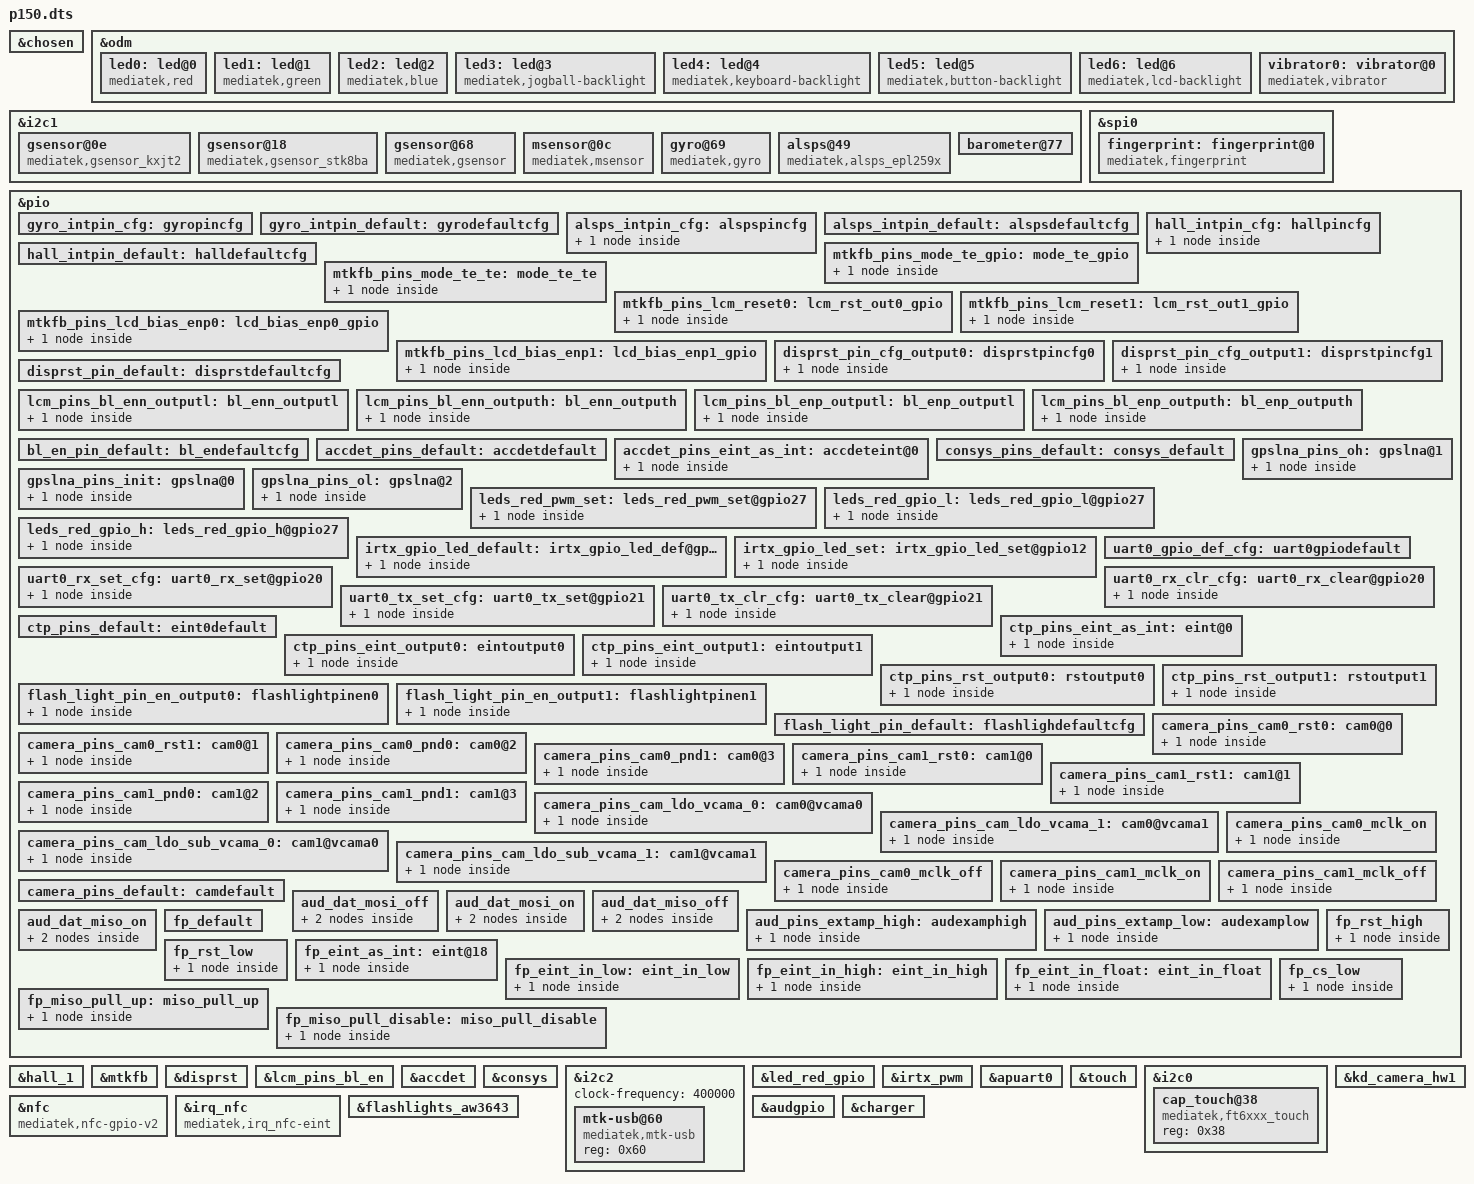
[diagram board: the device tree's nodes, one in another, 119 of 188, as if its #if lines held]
#include <generated/autoconf.h>
/dts-v1/;

#ifdef CONFIG_MTK_DTBO_FEATURE
/plugin/;
#include <dt-bindings/mmc/mt6739-msdc.h>
#include <dt-bindings/pinctrl/mt6739-pinfunc.h>
#else
#include "mt6739.dts"
#endif

#include <dt-bindings/clock/mt6739-clk.h>
#include <dt-bindings/interrupt-controller/arm-gic.h>
#include <dt-bindings/interrupt-controller/irq.h>

/* chosen */
&chosen {
	bootargs = "console=tty0 console=ttyMT0,921600n1 root=/dev/ram initrd=0x44000000,\
0x1000000 loglevel=8 androidboot.selinux=permissive androidboot.hardware=mt6739 initcall_debug=1";
	/* fpga may has no lk, we need to specify display info here */
	/* fb buffer is reserved using this dts by memory node above */

	atag,videolfb-fb_base_l = <0x5e605000>;
	atag,videolfb-fb_base_h = <0>;
	atag,videolfb-islcmfound = <1>;
	atag,videolfb-islcm_inited = <0>;
	atag,videolfb-fps= <6000>;
	atag,videolfb-vramSize= <0x017bb000>;
	atag,videolfb-lcmname= "nt35521_hd_dsi_vdo_truly_nt50358_drv";
};

&odm {
	led0:led@0 {
		compatible = "mediatek,red";
		led_mode = <1>;
		data = <2>;
		pwm_config = <0 0 0 0 0>;
	};
	led1:led@1 {
		compatible = "mediatek,green";
		led_mode = <3>;
		data = <2>;
		pwm_config = <0 0 0 0 0>;
	};
	led2:led@2 {
		compatible = "mediatek,blue";
		led_mode = <0>;
		data = <1>;
		pwm_config = <0 0 0 0 0>;
	};
	led3:led@3 {
		compatible = "mediatek,jogball-backlight";
		led_mode = <0>;
		data = <1>;
		pwm_config = <0 0 0 0 0>;
	};
	led4:led@4 {
		compatible = "mediatek,keyboard-backlight";
		led_mode = <0>;
		data = <1>;
		pwm_config = <0 0 0 0 0>;
	};
	led5:led@5 {
		compatible = "mediatek,button-backlight";
		led_mode = <0>;
		data = <1>;
		pwm_config = <0 0 0 0 0>;
	};
	led6:led@6 {
		compatible = "mediatek,lcd-backlight";
		led_mode = <5>;
		data = <1>;
		pwm_config = <0 0 0 0 0>;
	};
	vibrator0:vibrator@0 {
		compatible = "mediatek,vibrator";
		vib_timer = <25>;
		vib_limit = <9>;
		vib_vol= <9>;
	};
};


&i2c1 {
/*  start sensor */
	/*  KXTJ3, compatible with kxjt2 code*/
	gsensor@0e {
		compatible = "mediatek,gsensor_kxjt2";
		reg = <0x0e>;
		i2c_num	= <1>;
		i2c_addr = <0x0e 0 0 0>;
		direction = <1>;
		power_id = <0xffff>;
		power_vol = <0>;
		firlen = <16>;
		is_batch_supported = <0>;
	};

	gsensor@18 {
		compatible = "mediatek,gsensor_stk8ba";
		reg = <0x18>;
		i2c_num	= <1>;
		i2c_addr = <0x18 0 0 0>;
		direction = <5>;
		power_id = <0xffff>;
		power_vol = <0>;
		firlen = <16>;
		is_batch_supported = <0>;
	};	

		/* InvenSense ICM-20608D */
	gsensor@68 {
		compatible = "mediatek,gsensor";
		reg = <0x68>;
		i2c_num	= <1>;
		i2c_addr = <0x68 0 0 0>;
		direction = <4>;
		power_id = <0xffff>;
		power_vol = <0>;
		firlen = <16>;
		is_batch_supported = <0>;
	};
	
	/* akm09918 */
	msensor@0c {
		compatible = "mediatek,msensor";
		i2c_num = <1>;
		i2c_addr = <0x0c 0 0 0>;
		direction = <7>;  // 1  3  5
		power_id = <0xffff>;
		power_vol = <0>;
		is_batch_supported = <0>;
	};
	
	/* InvenSense ICM-20608D */
	gyro@69 {
		compatible = "mediatek,gyro";
		pinctrl-names = "pin_default", "pin_cfg";
		pinctrl-0 = <&gyro_intpin_default>;
		pinctrl-1 = <&gyro_intpin_cfg>;
		i2c_num = <1>;
		i2c_addr = <0x69 0 0 0>;
		direction = <4>;
		power_id = <0xffff>;
		power_vol = <0>;
		firlen = <0>;
		is_batch_supported = <0>;
	};


	/* Eminent MN26233T,compatible with epl259x */
	alsps@49 {
		compatible = "mediatek,alsps_epl259x";
		pinctrl-names = "pin_default", "pin_cfg";
		pinctrl-0 = <&alsps_intpin_default>;
		pinctrl-1 = <&alsps_intpin_cfg>;
		/* customization */
		reg = <0x49>;
		i2c_num = <1>;
		i2c_addr = <0x49 0 0 0>;
		polling_mode_ps = <0>;
		polling_mode_als = <1>;
		power_id = <0xffff>;
		power_vol = <0>;
		als_level = <26 62 129 250 2337 5363 8592 12533 17001 21710 26554 31860 65535 65535 

65535>;
		als_value = <0 38 95 190 1250 1500 1700 1920 2900 5745 8500 10000 10243 10243 10243>;
		ps_threshold_high = <1300>;
		ps_threshold_low = <800>;
		is_batch_supported_ps = <0>;
		is_batch_supported_als = <0>;
		status = "okay";
	}; 


	barometer@77 {
		i2c_num = <1>;
		i2c_addr = <0x77 0 0 0>;
		direction = <0>;
		power_id = <0xffff>;
		power_vol = <0>;
		firlen = <32>;
		is_batch_supported = <0>;
	};
/* end sensor */
};

&spi0 {
       fingerprint: fingerprint@0 { 
		compatible = "mediatek,fingerprint";
		spi-max-frequency = <1000000>;
		reg = <0x0>;
                interrupt-parent = <&pio>;
                interrupts = <18 IRQ_TYPE_EDGE_RISING 18 0>;
                status = "okay";
		clocks = <&topckgen CLK_TOP_SYSPLL3_D2>,
				<&topckgen CLK_TOP_SPI_SEL>,
				<&infracfg_ao CLK_INFRA_SPI0>;
		clock-names = "parent-clk", "sel-clk", "spi-clk"; 
        }; 
}; 

/* sensor gpio standization */
&pio {

	gyro_intpin_cfg: gyropincfg {
/*
	    pins_cmd_dat {
			pins = <PINMUX_GPIO119__FUNC_GPIO119>;
			slew-rate = <0>;
			bias-pull-down = <00>;
		};
*/
	};

	gyro_intpin_default: gyrodefaultcfg {

	};
};

&pio {
	alsps_intpin_cfg: alspspincfg {

		pins_cmd_dat {
			pins = <PINMUX_GPIO6__FUNC_GPIO6>;
			slew-rate = <0>;
			bias-pull-up = <MTK_PUPD_SET_R1R0_01>;
		};
	};

	alsps_intpin_default: alspsdefaultcfg {

	};
};

/* sensor end */

/*hall start*/
&pio {
	hall_intpin_cfg: hallpincfg {
	    pins_cmd_dat {
			pins = <PINMUX_GPIO9__FUNC_GPIO9>;
			slew-rate = <0>;
			bias-pull-up = <MTK_PUPD_SET_R1R0_01>;
		};
	};
	hall_intpin_default: halldefaultcfg {
	};

};
&hall_1 {
	pinctrl-names = "pin_default", "pin_cfg";
	pinctrl-0 = <&hall_intpin_default>;
	pinctrl-1 = <&hall_intpin_cfg>;
	status = "okay";
};
/*hall end*/


/* DISPSYS GPIO standardization */
&pio {
	mtkfb_pins_mode_te_gpio: mode_te_gpio {
		pins_cmd_dat {
			pins = <PINMUX_GPIO84__FUNC_DSI_TE>;
		};
	};

	mtkfb_pins_mode_te_te: mode_te_te {
		pins_cmd_dat {
			pins = <PINMUX_GPIO84__FUNC_DSI_TE>;
		};
	};

	mtkfb_pins_lcm_reset0: lcm_rst_out0_gpio {
		pins_cmd_dat {
			pins = <PINMUX_GPIO83__FUNC_LCM_RST>;
			slew-rate = <1>;
			output-low;
		};
	};

	mtkfb_pins_lcm_reset1: lcm_rst_out1_gpio {
		pins_cmd_dat {
			pins = <PINMUX_GPIO83__FUNC_LCM_RST>;
			slew-rate = <1>;
			output-high;
		};
	};

	mtkfb_pins_lcd_bias_enp0: lcd_bias_enp0_gpio {
		pins_cmd_dat {
			pins = <PINMUX_GPIO122__FUNC_GPIO122>;
			slew-rate = <1>;
			output-low;
		};
	};
	mtkfb_pins_lcd_bias_enp1: lcd_bias_enp1_gpio {
		pins_cmd_dat {
			pins = <PINMUX_GPIO122__FUNC_GPIO122>;
			slew-rate = <1>;
			output-high;
		};
	};

};

&mtkfb {
	pinctrl-names = "mode_te_gpio", "mode_te_te", "lcm_rst_out0_gpio",
		"lcm_rst_out1_gpio", "lcd_bias_enp0_gpio", "lcd_bias_enp1_gpio";
	pinctrl-0 = <&mtkfb_pins_mode_te_gpio>;
	pinctrl-1 = <&mtkfb_pins_mode_te_te>;
	pinctrl-2 = <&mtkfb_pins_lcm_reset0>;
	pinctrl-3 = <&mtkfb_pins_lcm_reset1>;
	pinctrl-4 = <&mtkfb_pins_lcd_bias_enp0>;
	pinctrl-5 = <&mtkfb_pins_lcd_bias_enp1>;
	status = "okay";
};
/* DISPSYS GPIO standardization end */

/*C300 DISPLAY BEGIN*/
&pio {
	disprst_pin_cfg_output0: disprstpincfg0 {
	    pins_cmd_dat {
			pins = <PINMUX_GPIO83__FUNC_GPIO83>;
			slew-rate = <1>;
			output-low;
		};
	};
	disprst_pin_cfg_output1: disprstpincfg1 {
	    pins_cmd_dat {
			pins = <PINMUX_GPIO83__FUNC_GPIO83>;
			slew-rate = <1>;
			output-high;
		};
	};
	disprst_pin_default: disprstdefaultcfg {
	};

};

&disprst {
	pinctrl-names = "disprstpin_default", "disprstpin_cfg0", "disprstpin_cfg1";
	pinctrl-0 = <&disprst_pin_default>;
	pinctrl-1 = <&disprst_pin_cfg_output0>;
	pinctrl-2 = <&disprst_pin_cfg_output1>;
	status = "okay";
};

&pio {
	lcm_pins_bl_enn_outputl: bl_enn_outputl {
		pins_cmd_dat {
			pins = <PINMUX_GPIO53__FUNC_GPIO53>;
			slew-rate = <1>;
			output-low;
		};
	};

	lcm_pins_bl_enn_outputh: bl_enn_outputh {
		pins_cmd_dat {
			pins = <PINMUX_GPIO53__FUNC_GPIO53>;
			slew-rate = <1>;
			output-high;
		};
	};
	lcm_pins_bl_enp_outputl: bl_enp_outputl {
		pins_cmd_dat {
			pins = <PINMUX_GPIO54__FUNC_GPIO54>;
			slew-rate = <1>;
			output-low;
		};
	};

	lcm_pins_bl_enp_outputh: bl_enp_outputh {
		pins_cmd_dat {
			pins = <PINMUX_GPIO54__FUNC_GPIO54>;
			slew-rate = <1>;
			output-high;
		};
	};
	
	bl_en_pin_default: bl_endefaultcfg {
	};
};

&lcm_pins_bl_en {
	pinctrl-names = "bl_en_pin_default","lcm_enn_outputl","lcm_enn_outputh",
			"lcm_enp_outputl","lcm_enp_outputh";
	pinctrl-0 = <&bl_en_pin_default>;
	pinctrl-1 = <&lcm_pins_bl_enn_outputl>;
	pinctrl-2 = <&lcm_pins_bl_enn_outputh>;
	pinctrl-3 = <&lcm_pins_bl_enp_outputl>;
	pinctrl-4 = <&lcm_pins_bl_enp_outputh>;
	lcm-id-gpios = <&pio 7 0>;
	status = "okay";
};
/*C300 DISPLAY END*/



/* accdet start */
&accdet {
	/* accdet micbias voltage: 0x07,2.7v;0x05,2.5v;0x02,1.9v */
	accdet-mic-vol = <6>;
	headset-mode-setting = <0x500 0x500 1 0x1f0 0x800 0x800 0x20 0x44>;
	accdet-plugout-debounce = <1>;
	/*1:ACC mode, 2:low cost without in bias, 6:low cost with in bias*/
	accdet-mic-mode = <2>;
	/* eint_level_trigger: 8,LEVEL_LOW(default);4,LEVEL_HIGH;others,LEVEL_LOW */
	headset-eint-level-pol = <8>;
	/*0--MD_MAX--UP_MAX--DW_MAX*/
	headset-three-key-threshold = <0 80 220 400>;
	headset-three-key-threshold-CDD = <0 121 192 600>;
	/*0--MD_MAX--VOICE_MAX--UP_MAX--DW_MAX*/
	headset-four-key-threshold = <0 58 121 192 400>;
	/* ACCDET GPIO standardization ACC mode no use */
	pinctrl-names = "default", "state_eint_as_int";
	pinctrl-0 = <&accdet_pins_default>;
	pinctrl-1 = <&accdet_pins_eint_as_int>;
	status = "okay";
};
&pio {
	accdet_pins_default: accdetdefault {
	};
	accdet_pins_eint_as_int: accdeteint@0 {
		pins_cmd_dat {
			/*pins = <PINMUX_GPIO11__FUNC_GPIO11>;*/
			slew-rate = <0>;
			bias-disable;
		};
	};
};
/* accdet end */
/* CONSYS GPIO standardization */
&pio {
	consys_pins_default: consys_default {
	};
	gpslna_pins_init: gpslna@0 {
		pins_cmd_dat {
			pins = <PINMUX_GPIO118__FUNC_GPIO118>;
			slew-rate = <0>;
			bias-disable;
			output-low;
		};
	};
	gpslna_pins_oh: gpslna@1 {
		pins_cmd_dat {
			pins = <PINMUX_GPIO118__FUNC_GPIO118>;
			slew-rate = <1>;
			output-high;
		};
	};
	gpslna_pins_ol: gpslna@2 {
		pins_cmd_dat {
			pins = <PINMUX_GPIO118__FUNC_GPIO118>;
			slew-rate = <1>;
			output-low;
		};
	};
};
&consys {
	pinctrl-names = "default", "gps_lna_state_init", "gps_lna_state_oh", "gps_lna_state_ol";
	pinctrl-0 = <&consys_pins_default>;
	pinctrl-1 = <&gpslna_pins_init>;
	pinctrl-2 = <&gpslna_pins_oh>;
	pinctrl-3 = <&gpslna_pins_ol>;
	status = "okay";
};
&i2c2 {
	#address-cells = <1>;
	#size-cells = <0>;
	clock-frequency = <400000>;

	mtk-usb@60 {
		compatible = "mediatek,mtk-usb";
		reg = <0x60>;
		status = "okay";
	};
};

&led_red_gpio {
	pinctrl-names = "leds_red_pwm_set","leds_red_gpio_l","leds_red_gpio_h";
	pinctrl-0 = <&leds_red_pwm_set>;
	pinctrl-1 = <&leds_red_gpio_l>;
	pinctrl-2 = <&leds_red_gpio_h>;
	status = "okay";
};
&pio {
	leds_red_pwm_set:leds_red_pwm_set@gpio27 {
		pins_cmd_dat {
			pins = <PINMUX_GPIO27__FUNC_PWM2>;
			slew-rate = <1>;
			output-high;
		};
	};
        leds_red_gpio_l:leds_red_gpio_l@gpio27 {
		pins_cmd_dat {
			pins = <PINMUX_GPIO27__FUNC_GPIO27>;
			slew-rate = <1>;
			output-low;
		};
	};
        leds_red_gpio_h:leds_red_gpio_h@gpio27 {
		pins_cmd_dat {
			pins = <PINMUX_GPIO27__FUNC_GPIO27>;
			slew-rate = <1>;
			output-high;
		};
	};
}; 
/* IRTX GPIO Start */
&irtx_pwm {
	pinctrl-names = "irtx_gpio_led_default", "irtx_gpio_led_set";
	pinctrl-0 = <&irtx_gpio_led_default>;
	pinctrl-1 = <&irtx_gpio_led_set>;
	status = "okay";
};
&pio {
	/* IRTX GPIO Settings -Start */
	/* default: GPIO0, output, high */
	irtx_gpio_led_default:irtx_gpio_led_def@gpio12 {
		pins_cmd_dat {
			pins = <PINMUX_GPIO12__FUNC_GPIO12>;
			slew-rate = <1>;
			bias-disable;
			output-low;
			input-schmitt-enable = <0>;
		};
	};

	irtx_gpio_led_set:irtx_gpio_led_set@gpio12 {
		pins_cmd_dat {
			pins = <PINMUX_GPIO12__FUNC_PWM1>;
			slew-rate = <1>;
			output-high;
		};
	};
}; /* IRTX GPIO Settings -End */

/* UART GPIO */
&apuart0 {
	pinctrl-names = "uart0_gpio_default",
			"uart0_rx_set",
			"uart0_rx_clear",
			"uart0_tx_set",
			"uart0_tx_clear";
	pinctrl-0 = <&uart0_gpio_def_cfg>;
	pinctrl-1 = <&uart0_rx_set_cfg>;
	pinctrl-2 = <&uart0_rx_clr_cfg>;
	pinctrl-3 = <&uart0_tx_set_cfg>;
	pinctrl-4 = <&uart0_tx_clr_cfg>;
	status = "okay";
};

&pio {
	/* UART GPIO Settings - Start */
	/* UART0: rx set, rx clear, tx clear, tx clear*/
	uart0_gpio_def_cfg:uart0gpiodefault {

	};
	uart0_rx_set_cfg:uart0_rx_set@gpio20 {
		pins_cmd_dat {
			pins = <PINMUX_GPIO20__FUNC_UART0RX>;
		};
	};
	uart0_rx_clr_cfg:uart0_rx_clear@gpio20 {
		pins_cmd_dat {
			pins = <PINMUX_GPIO20__FUNC_GPIO20>;
			slew-rate = <1>;
			output-high;
		};
	};
	uart0_tx_set_cfg:uart0_tx_set@gpio21 {
		pins_cmd_dat {
			pins = <PINMUX_GPIO21__FUNC_UART0TX>;
		};
	};
	uart0_tx_clr_cfg:uart0_tx_clear@gpio21 {
		pins_cmd_dat {
			pins = <PINMUX_GPIO21__FUNC_GPIO21>;
			slew-rate = <1>;
			output-high;
		};
	};
};/* UART GPIO end */

/* TOUCH start */
&touch {
	tpd-resolution = <720 1512>;
	use-tpd-button = <0>;
	tpd-key-num = <3>;
	tpd-key-local= <139 172 158 0>;
	tpd-key-dim-local = <90 883 100 40 230 883 100 40 370 883 100 40 0 0 0 0>;
	tpd-max-touch-num = <5>;
	tpd-filter-enable = <0>;
	tpd-filter-pixel-density = <106>;
	tpd-filter-custom-prameters = <0 0 0 0 0 0 0 0 0 0 0 0>;
	tpd-filter-custom-speed = <0 0 0>;
	pinctrl-names = "default", "state_eint_as_int", "state_eint_output0", "state_eint_output1",
		"state_rst_output0", "state_rst_output1";
	pinctrl-0 = <&ctp_pins_default>;
	pinctrl-1 = <&ctp_pins_eint_as_int>;
	pinctrl-2 = <&ctp_pins_eint_output0>;
	pinctrl-3 = <&ctp_pins_eint_output1>;
	pinctrl-4 = <&ctp_pins_rst_output0>;
	pinctrl-5 = <&ctp_pins_rst_output1>;
	status = "okay";
};
&pio {
	ctp_pins_default: eint0default {
	};
	ctp_pins_eint_as_int: eint@0 {
		pins_cmd_dat {
			pins = <PINMUX_GPIO14__FUNC_GPIO14>;
			slew-rate = <0>;
			bias-disable;
		};
	};
	ctp_pins_eint_output0: eintoutput0 {
		pins_cmd_dat {
			pins = <PINMUX_GPIO14__FUNC_GPIO14>;
			slew-rate = <1>;
			output-low;
		};
	};
	ctp_pins_eint_output1: eintoutput1 {
		pins_cmd_dat {
			pins = <PINMUX_GPIO14__FUNC_GPIO14>;
			slew-rate = <1>;
			output-high;
		};
	};
	ctp_pins_rst_output0: rstoutput0 {
		pins_cmd_dat {
			pins = <PINMUX_GPIO119__FUNC_GPIO119>;
			slew-rate = <1>;
			output-low;
		};
	};
	ctp_pins_rst_output1: rstoutput1 {
		pins_cmd_dat {
			pins = <PINMUX_GPIO119__FUNC_GPIO119>;
			slew-rate = <1>;
			output-high;
		};
	};
};


&i2c0 {
	cap_touch@38 {
		compatible = "mediatek,ft6xxx_touch";
		reg = <0x38>;
		status = "okay";
		};
	};

/* TOUCH end */

/* NFC start */
&nfc {
	compatible = "mediatek,nfc-gpio-v2";
	gpio-rst = <0>;
	gpio-rst-std = <&pio 0 0x0>;
	gpio-irq = <1>;
	gpio-irq-std = <&pio 1 0x0>;
};

&irq_nfc {
	compatible = "mediatek,irq_nfc-eint";
};
/* NFC end */
/* CAMERA GPIO standardization */
&pio {
            flash_light_pin_en_output0: flashlightpinen0 {
            pins_cmd_dat {
                        pins = <PINMUX_GPIO11__FUNC_GPIO11>;
                        slew-rate = <1>;
                        output-low;
                };
        };
        flash_light_pin_en_output1: flashlightpinen1 {
            pins_cmd_dat {
                        pins = <PINMUX_GPIO11__FUNC_GPIO11>;
                        slew-rate = <1>;
                        output-high;
                };
        };
  		 flash_light_pin_default: flashlighdefaultcfg {
        };

};
&flashlights_aw3643 {
        pinctrl-names = "flashlightpin_default", "flashlightpin_en0","flashlightpin_en1";
        pinctrl-0 = <&flash_light_pin_default>;
        pinctrl-1 = <&flash_light_pin_en_output0>;
        pinctrl-2 = <&flash_light_pin_en_output1>;
        status = "okay";
};
/* CAMERA GPIO standardization */
&pio {
	camera_pins_cam0_rst0: cam0@0 {
		pins_cmd_dat {
			pins = <PINMUX_GPIO29__FUNC_GPIO29>;
			slew-rate = <1>; /*direction 0:in, 1:out*/
			output-low;/*direction out used only. output_low or high*/
		};
	};
	camera_pins_cam0_rst1: cam0@1 {
		pins_cmd_dat {
			pins = <PINMUX_GPIO29__FUNC_GPIO29>;
			slew-rate = <1>;
			output-high;
		};
	};
	camera_pins_cam0_pnd0: cam0@2 {
		pins_cmd_dat {
			pins = <PINMUX_GPIO3__FUNC_GPIO3>;
			slew-rate = <1>;
			output-low;
		};
	};
	camera_pins_cam0_pnd1: cam0@3 {
		pins_cmd_dat {
			pins = <PINMUX_GPIO3__FUNC_GPIO3>;
			slew-rate = <1>;
			output-high;
		};
	};
	camera_pins_cam1_rst0: cam1@0 {
		pins_cmd_dat {
			pins = <PINMUX_GPIO22__FUNC_GPIO22>;
			slew-rate = <1>; /*direction 0:in, 1:out*/
			output-low;/*direction out used only. output_low or high*/
		};
	};
	camera_pins_cam1_rst1: cam1@1 {
		pins_cmd_dat {
			pins = <PINMUX_GPIO22__FUNC_GPIO22>;
			slew-rate = <1>;
			output-high;
		};
	};
	camera_pins_cam1_pnd0: cam1@2 {
		pins_cmd_dat {
			pins = <PINMUX_GPIO25__FUNC_GPIO25>;
			slew-rate = <1>;
			output-low;
		};
	};
	camera_pins_cam1_pnd1: cam1@3 {
		pins_cmd_dat {
			pins = <PINMUX_GPIO25__FUNC_GPIO25>;
			slew-rate = <1>;
			output-high;
		};
	};
	camera_pins_cam_ldo_vcama_0: cam0@vcama0 {
		pins_cmd_dat {
			pins = <PINMUX_GPIO13__FUNC_GPIO13>;
			slew-rate = <1>;
			output-low;
		};
	};
	camera_pins_cam_ldo_vcama_1: cam0@vcama1 {
		pins_cmd_dat {
			pins = <PINMUX_GPIO13__FUNC_GPIO13>;
			slew-rate = <1>;
			output-high;
		};
};
	camera_pins_cam_ldo_sub_vcama_0: cam1@vcama0 {
		pins_cmd_dat {
			pins = <PINMUX_GPIO13__FUNC_GPIO13>;
			slew-rate = <1>;
			output-low;
		};
	};
	camera_pins_cam_ldo_sub_vcama_1: cam1@vcama1 {
		pins_cmd_dat {
			pins = <PINMUX_GPIO13__FUNC_GPIO13>;
			slew-rate = <1>;
			output-high;
		};
	};
	camera_pins_cam0_mclk_on: camera_pins_cam0_mclk_on {
		pins_cmd_dat {
			pins = <PINMUX_GPIO126__FUNC_CMMCLK0>;
		};
	};
	camera_pins_cam0_mclk_off: camera_pins_cam0_mclk_off {
		pins_cmd_dat {
			pins = <PINMUX_GPIO126__FUNC_GPIO126>;
		};
	};
	camera_pins_cam1_mclk_on: camera_pins_cam1_mclk_on {
		pins_cmd_dat {
			pins = <PINMUX_GPIO127__FUNC_CMMCLK1>;
		};
	};
	camera_pins_cam1_mclk_off: camera_pins_cam1_mclk_off {
		pins_cmd_dat {
			pins = <PINMUX_GPIO127__FUNC_GPIO127>;
		};
	};
	camera_pins_default: camdefault {
	};
};

&kd_camera_hw1 {
	pinctrl-names = "default",
			"cam0_rst0", "cam0_rst1", "cam0_pnd0", "cam0_pnd1",
			"cam1_rst0", "cam1_rst1", "cam1_pnd0", "cam1_pnd1",
			"cam_ldo_vcama_0", "cam_ldo_vcama_1", "cam_ldo_sub_vcama_0", 
			"cam_ldo_sub_vcama_1", "cam0_mclk_on", "cam0_mclk_off",
			"cam1_mclk_on", "cam1_mclk_off";

	pinctrl-0 = <&camera_pins_default>;
	pinctrl-1 = <&camera_pins_cam0_rst0>;
	pinctrl-2 = <&camera_pins_cam0_rst1>;
	pinctrl-3 = <&camera_pins_cam0_pnd0>;
	pinctrl-4 = <&camera_pins_cam0_pnd1>;
	pinctrl-5 = <&camera_pins_cam1_rst0>;
	pinctrl-6 = <&camera_pins_cam1_rst1>;
	pinctrl-7 = <&camera_pins_cam1_pnd0>;
	pinctrl-8 = <&camera_pins_cam1_pnd1>;
    pinctrl-9 = <&camera_pins_cam_ldo_vcama_0>;
	pinctrl-10 = <&camera_pins_cam_ldo_vcama_1>;
	pinctrl-11 = <&camera_pins_cam_ldo_sub_vcama_0>;
	pinctrl-12 = <&camera_pins_cam_ldo_sub_vcama_1>;
	pinctrl-13 = <&camera_pins_cam0_mclk_on>;
	pinctrl-14 = <&camera_pins_cam0_mclk_off>;
	pinctrl-15 = <&camera_pins_cam1_mclk_on>;
	pinctrl-16 = <&camera_pins_cam1_mclk_off>;
	status = "okay";

};
/* CAMERA GPIO end */

/* AUDIO GPIO standardization */
&audgpio {
	pinctrl-names = "aud_dat_mosi_off",
			"aud_dat_mosi_on",
			"aud_dat_miso_off",
			"aud_dat_miso_on",
			"extamp-pullhigh",
			"extamp-pulllow";
	pinctrl-0 = <&aud_dat_mosi_off>;
	pinctrl-1 = <&aud_dat_mosi_on>;
	pinctrl-2 = <&aud_dat_miso_off>;
	pinctrl-3 = <&aud_dat_miso_on>;
	pinctrl-4 = <&aud_pins_extamp_high>;
	pinctrl-5 = <&aud_pins_extamp_low>;
	status = "okay";
};

&pio {
	aud_dat_mosi_off: aud_dat_mosi_off {
		pins_cmd1_dat {
			pins = <PINMUX_GPIO63__FUNC_GPIO63>;
			input-enable;
			slew-rate = <0>;
			bias-disable;
		};
		pins_cmd2_dat {
			pins = <PINMUX_GPIO64__FUNC_GPIO64>;
			input-enable;
			slew-rate = <0>;
			bias-disable;
		};
	};

	aud_dat_mosi_on: aud_dat_mosi_on {
		pins_cmd1_dat {
			pins = <PINMUX_GPIO63__FUNC_AUD_DAT_MOSI0>;
		};
		pins_cmd2_dat {
			pins = <PINMUX_GPIO64__FUNC_AUD_DAT_MOSI1>;
		};
	};

	aud_dat_miso_off: aud_dat_miso_off {
		pins_cmd1_dat {
			pins = <PINMUX_GPIO67__FUNC_GPIO67>;
			input-enable;
			slew-rate = <0>;
			bias-disable;
		};
		pins_cmd2_dat {
			pins = <PINMUX_GPIO68__FUNC_GPIO68>;
			input-enable;
			slew-rate = <0>;
			bias-disable;
		};
	};

	aud_dat_miso_on: aud_dat_miso_on {
		pins_cmd1_dat {
			pins = <PINMUX_GPIO67__FUNC_AUD_DAT_MISO0>;
		};
		pins_cmd2_dat {
			pins = <PINMUX_GPIO68__FUNC_AUD_DAT_MISO1>;
		};
	};
	aud_pins_extamp_high: audexamphigh {
		pins_cmd_dat {
			pins = <PINMUX_GPIO4__FUNC_GPIO4>;
			slew-rate = <1>;
			output-high;
		};
	};

	aud_pins_extamp_low: audexamplow {
		pins_cmd_dat {
			pins = <PINMUX_GPIO4__FUNC_GPIO4>;
			slew-rate = <1>;
			output-low;
		};
	};

};
/* AUDIO end */

/* Fingerprint GPIO start */
&pio {
	fp_default: fp_default {
	};

	fp_rst_high: fp_rst_high {
		pins_cmd_dat {
			pins = <PINMUX_GPIO19__FUNC_GPIO19>;
			slew-rate = <1>;
			output-high;
		};
	};

	fp_rst_low: fp_rst_low {
		pins_cmd_dat {
			pins = <PINMUX_GPIO19__FUNC_GPIO19>;
			slew-rate = <1>;
			output-low;
		};
	};


	fp_eint_as_int: eint@18 {
		pins_cmd_dat {
			pins = <PINMUX_GPIO18__FUNC_GPIO18>;
			slew-rate = <0>;
			bias-disable;
		};
	};
	fp_eint_in_low: eint_in_low {
		pins_cmd_dat {
			pins = <PINMUX_GPIO18__FUNC_GPIO18>;
			slew-rate = <0>;
			bias-pull-down = <00>;
		};
	};
	fp_eint_in_high: eint_in_high {
		pins_cmd_dat {
			pins = <PINMUX_GPIO18__FUNC_GPIO18>;
			slew-rate = <0>;
			bias-pull-up = <00>;
		};
	};
	fp_eint_in_float: eint_in_float {
		pins_cmd_dat {
			pins = <PINMUX_GPIO18__FUNC_GPIO18>;
			slew-rate = <0>;
			bias-disable;
		};
	};
	fp_miso_pull_up: miso_pull_up {
		pins_cmd_dat {
			pins = <PINMUX_GPIO33__FUNC_GPIO33>;
			slew-rate = <0>;
			bias-pull-up = <00>;
		};
	};
	fp_miso_pull_disable: miso_pull_disable {
		pins_cmd_dat {
			pins = <PINMUX_GPIO33__FUNC_SPI0_A_MI>;
			bias-disable;
		};
	};
	fp_cs_low:  fp_cs_low{
		pins_cmd_dat {
			pins = <PINMUX_GPIO31__FUNC_GPIO31>;
			slew-rate = <0>;
			bias-pull-down = <00>;
		};
	};

};

&fingerprint {
	pinctrl-names = "fp_default", "fp_rst_high", "fp_rst_low","eint_as_int", "eint_in_low", "eint_in_float", "miso_pull_up", "miso_pull_disable" ,"eint_in_high";

	pinctrl-0 = <&fp_default>;
	pinctrl-1 = <&fp_rst_high>;
	pinctrl-2 = <&fp_rst_low>;
	pinctrl-3 = <&fp_eint_as_int>;
	pinctrl-4 = <&fp_eint_in_low>;
	pinctrl-5 = <&fp_eint_in_float>;
	pinctrl-6 = <&fp_miso_pull_up>;
	pinctrl-7 = <&fp_miso_pull_disable>;
	pinctrl-8 = <&fp_eint_in_high>;
	status = "okay";

};
/* Fingerprint end */


//Added by zhengquan.qin
&charger {
		algorithm_name = "SwitchCharging";
		enable_sw_jeita; 
		enable_pe_plus;
		enable_pe_2;
		enable_pe_3;

		/* common */
		battery_cv = <4400000>;
		max_charger_voltage = <6500000>;

		/* charging current */
		usb_charger_current_suspend = <0>;
		usb_charger_current_unconfigured = <70000>;
		usb_charger_current_configured = <500000>;
		usb_charger_current = <500000>;
		ac_charger_current = <1500000>;
		ac_charger_input_current = <1500000>;
		non_std_ac_charger_current = <500000>;
		charging_host_charger_current = <500000>;
		apple_1_0a_charger_current = <650000>;
		apple_2_1a_charger_current = <800000>;
		ta_ac_charger_current = <3000000>;

		/* sw jeita */
		jeita_temp_above_t4_cv_voltage = <4240000>;
		jeita_temp_t3_to_t4_cv_voltage = <4240000>;
		jeita_temp_t2_to_t3_cv_voltage = <4340000>;
		jeita_temp_t1_to_t2_cv_voltage = <4240000>;
		jeita_temp_t0_to_t1_cv_voltage = <4040000>;
		jeita_temp_below_t0_cv_voltage = <4040000>;
		temp_t4_threshold = <50>;
		temp_t4_thres_minus_x_degree = <47>;
		temp_t3_threshold = <45>;
		temp_t3_thres_minus_x_degree = <39>;
		temp_t2_threshold = <10>;
		temp_t2_thres_plus_x_degree = <16>;
		temp_t1_threshold = <0>;
		temp_t1_thres_plus_x_degree = <6>;
		temp_t0_threshold = <0>;
		temp_t0_thres_plus_x_degree = <0>;
		temp_neg_10_threshold = <0>;

		/* battery temperature protection */
		enable_min_charge_temperature;
		min_charge_temperature = <0>;
		min_charge_temperature_plus_x_degree = <6>;
		max_charge_temperature = <50>;
		max_charge_temperature_minus_x_degree = <47>;

		/* PE 2.0 */
		pe20_ichg_level_threshold = <1000>;
		ta_start_battery_soc = <0>;
		ta_stop_battery_soc = <85>;

		/* dual charger */
		chg1_ta_ac_charger_current = <1500000>;
		chg2_ta_ac_charger_current = <1500000>;

		/* cable measurement impedance */
		cable_imp_threshold = <699>;
		vbat_cable_imp_threshold = <3900>;

		/* bif */
		bif_threshold1 = <4250000>;
		bif_threshold2 = <4300000>;
		bif_cv_under_threshold2 = <4450000>;

		/* SW safety timer */
		enable_sw_safety_timer;
		max_charging_time = <43200>; /* 12 hours */

		/* linear charger */
		recharge_offset = <150000>;
		topoff_voltage = <4200000>;
		chg_full_current = <150000>;
};


//Added by zhengquan.qin,for porting bq24296 driver
#ifdef CONFIG_MTK_BQ24296_SUPPORT
#include "bq24296.dtsi"
#endif

//Added by zhengquan.qin,for porting bq2560x driver
#ifdef CONFIG_MTK_BQ2560X_SUPPORT
#include "bq2560x.dtsi"
#endif

#ifdef CONFIG_MTK_BQ24157_SUPPORT
#include "bq24157.dtsi"
#endif

#include <p150/cust.dtsi>
/*End of this file, DO NOT ADD ANYTHING HERE*/
